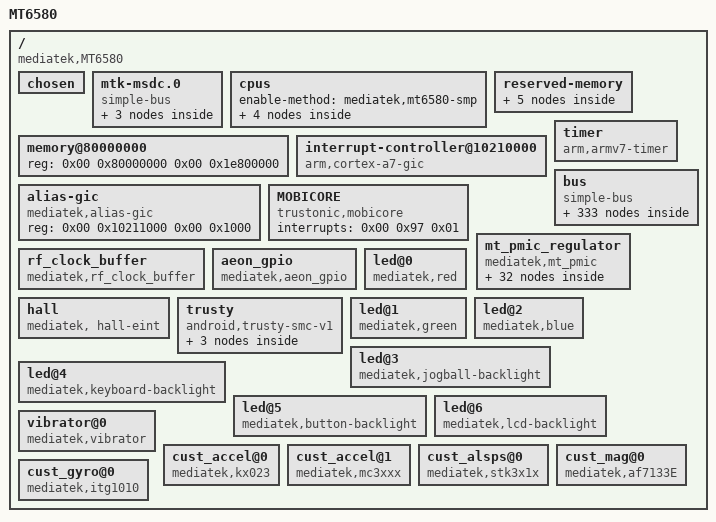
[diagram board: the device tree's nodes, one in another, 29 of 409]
/dts-v1/;

/ {
	model = "MT6580";
	compatible = "mediatek,MT6580";
	interrupt-parent = <0x01>;
	#address-cells = <0x02>;
	#size-cells = <0x02>;

	chosen {
		bootargs = "console=tty0 console=ttyMT0,921600n1 root=/dev/ram initrd=0x84000000,0x400000 loglevel=8";
		atag,videolfb-fb_base = <0x9e800000>;
		atag,videolfb-islcmfound = <0x01>;
		atag,videolfb-fps = <0x1770>;
		atag,videolfb-vramSize = <0x1800000>;
		atag,videolfb-lcmname = "nt35590_AUO";
	};

	mtk-msdc.0 {
		compatible = "simple-bus";
		#address-cells = <0x01>;
		#size-cells = <0x01>;
		ranges = <0x00 0x00 0x00 0xffffffff>;

		msdc0@11120000 {
			compatible = "mediatek,mt6580-mmc";
			reg = <0x11120000 0x10000 0x10001e84 0x02>;
			interrupts = <0x00 0x26 0x08>;
			status = "okay";
			clk_src = [07];
			bus-width = <0x08>;
			max-frequency = <0xc65d400>;
			cap-mmc-highspeed;
			msdc-sys-suspend;
			mmc-hs200-1_8v;
			non-removable;
			pinctl = <0x02>;
			register_setting = <0x03>;
			host_function = [00];
			bootable;
		};

		msdc1@11130000 {
			compatible = "mediatek,mt6580-mmc";
			reg = <0x11130000 0x10000 0x10001e84 0x02>;
			interrupts = <0x00 0x27 0x08>;
			cd-gpios = <0x04 0x0c 0x00>;
			status = "okay";
			clk_src = [02];
			bus-width = <0x04>;
			max-frequency = <0xc65d400>;
			msdc-sys-suspend;
			cap-sd-highspeed;
			sd-uhs-sdr12;
			sd-uhs-sdr25;
			sd-uhs-sdr50;
			sd-uhs-sdr104;
			non-removable;
			pinctl = <0x05>;
			pinctl_sdr104 = <0x06>;
			pinctl_sdr50 = <0x07>;
			pinctl_ddr50 = <0x08>;
			register_setting = <0x09>;
			host_function = [01];
			cd_level = [00];
		};

		default {
			compatible = "mediatek,msdc1_ins-eint";
			interrupt-parent = <0x0a>;
			interrupts = <0x0c 0x08>;
			debounce = <0x0c 0x3e8>;
			status = "okay";
		};
	};

	cpus {
		#address-cells = <0x01>;
		#size-cells = <0x00>;
		enable-method = "mediatek,mt6580-smp";

		cpu@0 {
			device_type = "cpu";
			compatible = "arm,cortex-a7";
			reg = <0x00>;
			clock-frequency = <0x6553f100>;
		};

		cpu@1 {
			device_type = "cpu";
			compatible = "arm,cortex-a7";
			reg = <0x01>;
			clock-frequency = <0x6553f100>;
		};

		cpu@2 {
			device_type = "cpu";
			compatible = "arm,cortex-a7";
			reg = <0x02>;
			clock-frequency = <0x6553f100>;
		};

		cpu@3 {
			device_type = "cpu";
			compatible = "arm,cortex-a7";
			reg = <0x03>;
			clock-frequency = <0x6553f100>;
		};
	};

	memory@80000000 {
		device_type = "memory";
		reg = <0x00 0x80000000 0x00 0x1e800000>;
	};

	reserved-memory {
		#address-cells = <0x02>;
		#size-cells = <0x02>;
		ranges;

		consys-reserve-memory {
			compatible = "mediatek,consys-reserve-memory";
			no-map;
			size = <0x00 0x200000>;
			alignment = <0x00 0x200000>;
		};

		reserve-memory-ccci_md1 {
			compatible = "mediatek,reserve-memory-ccci_md1";
			no-map;
			size = <0x00 0x1800000>;
			alignment = <0x00 0x2000000>;
			alloc-ranges = <0x00 0x80000000 0x00 0x80000000>;
		};

		pstore-reserved-memory@83f10000 {
			compatible = "mediatek,pstore";
			reg = <0x00 0x83f10000 0x00 0xe0000>;
		};

		ram_console-reserved-memory@83f00000 {
			compatible = "mediatek,ram_console";
			reg = <0x00 0x83f00000 0x00 0x10000>;
		};

		minirdump-reserved-memory@83ff0000 {
			compatible = "mediatek, minirdump";
			reg = <0x00 0x83ff0000 0x00 0x10000>;
		};
	};

	interrupt-controller@10210000 {
		compatible = "arm,cortex-a7-gic";
		#interrupt-cells = <0x03>;
		#address-cells = <0x00>;
		interrupt-controller;
		reg = <0x00 0x10211000 0x00 0x1000 0x00 0x10212000 0x00 0x1000 0x00 0x10200100 0x00 0x1000>;
		interrupts = <0x01 0x09 0xf04>;
		linux,phandle = <0x01>;
		phandle = <0x01>;
	};

	alias-gic {
		compatible = "mediatek,alias-gic";
		reg = <0x00 0x10211000 0x00 0x1000>;
	};

	timer {
		compatible = "arm,armv7-timer";
		interrupts = <0x01 0x0d 0x08 0x01 0x0e 0x08 0x01 0x0b 0x08 0x01 0x0a 0x08>;
		clock-frequency = <0xc65d40>;
	};

	bus {
		compatible = "simple-bus";
		#address-cells = <0x01>;
		#size-cells = <0x01>;
		ranges = <0x00 0x00 0x00 0xffffffff>;

		chipid@08000000 {
			compatible = "mediatek,chipid";
			reg = <0x8000000 0x04 0x8000004 0x04 0x8000008 0x04 0x800000c 0x04>;
		};

		TOPCKGEN@0x10000000 {
			compatible = "mediatek,TOPCKGEN";
			reg = <0x10000000 0x1000>;
		};

		INFRACFG_AO@0x10001000 {
			compatible = "mediatek,INFRACFG_AO";
			reg = <0x10001000 0x1000>;
		};

		bat_meter {
			compatible = "mediatek,bat_meter";
		};

		BAT_NOTIFY {
			compatible = "mediatek,bat_notify";
		};

		bat_comm {
			compatible = "mediatek,battery";
		};

		keypad@10002000 {
			compatible = "mediatek,mt6580-keypad";
			reg = <0x10002000 0x1000>;
			interrupts = <0x00 0x6d 0x02>;
			mediatek,kpd-key-debounce = <0x400>;
			mediatek,kpd-sw-pwrkey = <0x74>;
			mediatek,kpd-hw-pwrkey = <0x08>;
			mediatek,kpd-use-extend-type = <0x00>;
			mediatek,kpd-hw-map-num = <0x48>;
			mediatek,kpd-hw-init-map = <0x73 0x00 0x00 0x00 0x00 0x00 0x00 0x00 0x00 0x72 0x00 0x00 0x00 0x00 0x00 0x00 0x00 0x00 0x00 0x00 0x00 0x00 0x00 0x00 0x00 0x00 0x00 0x00 0x00 0x00 0x00 0x00 0x00 0x00 0x00 0x00 0x00 0x00 0x00 0x00 0x00 0x00 0x00 0x00 0x00 0x00 0x00 0x00 0x00 0x00 0x00 0x00 0x00 0x00 0x00 0x00 0x00 0x00 0x00 0x00 0x00 0x00 0x00 0x00 0x00 0x00 0x00 0x00 0x00 0x00 0x00 0x00>;
			mediatek,kpd-pwrkey-eint-gpio = <0x00>;
			mediatek,kpd-pwkey-gpio-din = <0x00>;
			mediatek,kpd-hw-dl-key0 = <0x00>;
			mediatek,kpd-hw-dl-key1 = <0x09>;
			mediatek,kpd-hw-dl-key2 = <0x08>;
			mediatek,kpd-hw-recovery-key = <0x00>;
			mediatek,kpd-hw-factory-key = <0x09>;
			status = "okay";
		};

		PERICFG@0x10003000 {
			compatible = "mediatek,PERICFG";
			reg = <0x10003000 0x1000>;
		};

		RESERVED@0x10004000 {
			compatible = "mediatek,RESERVED";
			reg = <0x10004000 0x1000>;
		};

		gpio {
			compatible = "mediatek,gpio_usage_mapping";
			GPIO_SIM1_SCLK = <0x16>;
			GPIO_SIM1_SIO = <0x17>;
			GPIO_SIM2_SIO = <0x18>;
			GPIO_SIM2_SCLK = <0x19>;
		};

		gpio@0x10005000 {
			compatible = "mediatek,gpio";
			reg = <0x10005000 0x1000>;
		};

		SLEEP@0x10006000 {
			compatible = "mediatek,SLEEP";
			reg = <0x10006000 0x1000>;
			interrupts = <0x00 0x58 0x08 0x00 0x59 0x08 0x00 0x5a 0x08 0x00 0x5b 0x08>;
		};

		TOPRGU@0x10007000 {
			compatible = "mediatek,TOPRGU";
			reg = <0x10007000 0x1000>;
			interrupts = <0x00 0x9d 0x02>;
		};

		APXGPT@0x10008000 {
			compatible = "mediatek,APXGPT";
			reg = <0x10008000 0x1000>;
			interrupts = <0x00 0x5c 0x08>;
			clock-frequency = <0xc65d40>;
		};

		EFUSEC@0x10009000 {
			compatible = "mediatek,EFUSEC";
			reg = <0x10009000 0x1000>;
		};

		hacc@0x1000A000 {
			compatible = "mediatek,hacc";
			reg = <0x1000a000 0x1000>;
			interrupts = <0x00 0x6e 0x00>;
		};

		cpu_dbgapb@10170000 {
			compatible = "mediatek,mt6580-dbg_debug";
			num = <0x04>;
			reg = <0x10170000 0x2000 0x10172000 0x2000 0x10174000 0x2000 0x10176000 0x2000>;
		};

		eintc@1000b000 {
			compatible = "mediatek,mt-eic";
			reg = <0x1000b000 0x1000>;
			interrupts = <0x00 0x5e 0x04>;
			#interrupt-cells = <0x02>;
			interrupt-controller;
			mediatek,max_eint_num = <0x1a>;
			mediatek,mapping_table_entry = <0x53>;
			mediatek,mapping_table = <0x00 0x00 0x01 0x01 0x02 0x02 0x03 0x03 0x04 0x04 0x05 0x05 0x06 0x06 0x07 0x07 0x08 0x08 0x09 0x09 0x0a 0x0a 0x0b 0x0b 0x0c 0x0c 0x0d 0x0d 0x0e 0x0e 0x0f 0x0f 0x10 0x00 0x11 0x01 0x12 0x02 0x13 0x03 0x14 0x04 0x15 0x05 0x16 0x06 0x17 0x07 0x18 0x08 0x19 0x09 0x1a 0x0a 0x1b 0x0b 0x1c 0x0c 0x1d 0x0d 0x1e 0x0e 0x1f 0x0f 0x20 0x00 0x21 0x01 0x22 0x02 0x23 0x03 0x24 0x04 0x25 0x05 0x26 0x06 0x27 0x07 0x28 0x08 0x29 0x09 0x2a 0x0a 0x2b 0x0b 0x2c 0x0c 0x2d 0x0d 0x2e 0x0e 0x2f 0x0f 0x30 0x00 0x31 0x01 0x32 0x02 0x33 0x03 0x34 0x03 0x35 0x04 0x36 0x05 0x37 0x06 0x38 0x07 0x39 0x08 0x3a 0x0a 0x3b 0x0b 0x3c 0x0c 0x3d 0x0d 0x3e 0x0e 0x3f 0x0f 0x40 0x00 0x41 0x01 0x42 0x02 0x43 0x03 0x44 0x10 0x45 0x04 0x46 0x05 0x47 0x06 0x48 0x07 0x49 0x08 0x4a 0x09 0x4b 0x0a 0x4c 0x0b 0x4d 0x0c 0x4e 0x0d 0x51 0x00 0x52 0x01 0x53 0x02 0x54 0x03>;
			mediatek,builtin_entry = <0x0b>;
			mediatek,builtin_mapping = <0x00 0x03 0x14 0x01 0x03 0x12 0x07 0x04 0x14 0x08 0x04 0x12 0x09 0x03 0x14 0x0a 0x03 0x12 0x18 0x05 0x14 0x19 0x05 0x12 0x4d 0x02 0x14 0x4e 0x02 0x12 0x0d 0x01 0x11>;
			linux,phandle = <0x0a>;
			phandle = <0x0a>;

			pmic@13 {
				compatible = "mediatek, pmic-eint";
				interrupt-parent = <0x0a>;
				interrupts = <0x0d 0x01>;
				debounce = <0x0d 0x3e8>;
			};
		};

		ap_ccif0@1000C000 {
			compatible = "mediatek,ap_ccif0";
			reg = <0x1000c000 0x1000 0x1000d000 0x1000>;
			interrupts = <0x00 0x5d 0x08 0x00 0x98 0x02>;
			mediatek,ccif_capability = <0x02>;
			mediatek,md_smem_size = <0x200000>;
		};

		MCUSYS_CFGREG@0x1020000 {
			compatible = "mediatek,MCUSYS_CFGREG_BASE";
			reg = <0x1020000 0x200>;
		};

		mcucfg@10200000 {
			compatible = "mediatek,mt6580-mcucfg";
			reg = <0x10200000 0x200>;
		};

		AES@0x1000E000 {
			compatible = "mediatek,AES";
			reg = <0x1000e000 0x1000>;
		};

		PWRAP@0x1000F000 {
			compatible = "mediatek,PWRAP";
			reg = <0x1000f000 0x1000>;
			interrupts = <0x00 0x6c 0x00>;
		};

		DEVAPC_AO@0x10010000 {
			compatible = "mediatek,DEVAPC_AO";
			reg = <0x10010000 0x1000>;
		};

		MIPI_CONFG@0x10011000 {
			compatible = "mediatek,MIPI_CONFG";
			reg = <0x10011000 0x1000>;
		};

		INFRA_MBIST@0x10012000 {
			compatible = "mediatek,INFRA_MBIST";
			reg = <0x10012000 0x1000>;
		};

		RESERVED@0x10013000 {
			compatible = "mediatek,RESERVED";
			reg = <0x10013000 0x1000>;
		};

		IOCFG_T@0x10014000 {
			compatible = "mediatek,IOCFG_T";
			reg = <0x10014000 0x1000>;
		};

		IOCFG_B@0x10015000 {
			compatible = "mediatek,IOCFG_B";
			reg = <0x10015000 0x1000>;
		};

		IOCFG_L@0x10016000 {
			compatible = "mediatek,IOCFG_L";
			reg = <0x10016000 0x1000>;
		};

		IOCFG_R@0x10017000 {
			compatible = "mediatek,IOCFG_R";
			reg = <0x10017000 0x1000>;
		};

		APMIXED@0x10018000 {
			compatible = "mediatek,APMIXED";
			reg = <0x10018000 0x1000>;
		};

		MCUCFG@0x10200000 {
			compatible = "mediatek,MCUCFG";
			reg = <0x10200000 0x1000>;
		};

		INFRACFG@0x10201000 {
			compatible = "mediatek,INFRACFG";
			reg = <0x10201000 0x1000>;
		};

		sys_cirq@10202000 {
			compatible = "mediatek,mt6580-sys_cirq\0mediatek,mt6735-sys_cirq";
			reg = <0x10202000 0x1000>;
			interrupts = <0x00 0x9e 0x08>;
			mediatek,cirq_num = <0x7e>;
			mediatek,spi_start_offset = <0x20>;
		};

		m4u@10203000 {
			cell-index = <0x00>;
			compatible = "mediatek,m4u";
			reg = <0x10203000 0x1000>;
			interrupts = <0x00 0x51 0x08>;
		};

		DEVAPC@0x10204000 {
			compatible = "mediatek,DEVAPC";
			reg = <0x10204000 0x1000>;
			interrupts = <0x00 0x4a 0x08>;
		};

		EMI@0x10205000 {
			compatible = "mediatek,EMI";
			reg = <0x10205000 0x1000>;
			interrupts = <0x00 0x4c 0x04>;
		};

		DRAMC_NAO@0x10206000 {
			compatible = "mediatek,DRAMC_NAO";
			reg = <0x10206000 0x1000>;
		};

		DRAMC0@0x10207000 {
			compatible = "mediatek,DRAMC0";
			reg = <0x10207000 0x1000>;
		};

		DDRPHY@0x10208000 {
			compatible = "mediatek,DDRPHY";
			reg = <0x10208000 0x1000>;
		};

		SRAMROM@0x10209000 {
			compatible = "mediatek,SRAMROM";
			reg = <0x10209000 0x1000>;
		};

		simswitch@0 {
			compatible = "mediatek,sim_switch";
			pinctrl-names = "default\0hot_plug_mode1";
			pinctrl-0 = <0x0b>;
			pinctrl-1 = <0x0c>;
		};

		gce@1020a000 {
			compatible = "mediatek,gce";
			reg = <0x1020a000 0x1000>;
			interrupts = <0x00 0x55 0x08 0x00 0x56 0x08>;
			disp_mutex_reg = <0x14015000 0x1000>;
			g3d_config_base = <0x13000000 0x00 0xffff0000>;
			mmsys_config_base = <0x14000000 0x01 0xffff0000>;
			disp_dither_base = <0x14010000 0x02 0xffff0000>;
			mm_na_base = <0x14020000 0x03 0xffff0000>;
			imgsys_base = <0x15000000 0x04 0xffff0000>;
			vdec_gcon_base = <0x16000000 0x05 0xffff0000>;
			venc_gcon_base = <0x17000000 0x06 0xffff0000>;
			conn_peri_base = <0x18000000 0x07 0xffff0000>;
			topckgen_base = <0x10000000 0x08 0xffff0000>;
			kp_base = <0x10010000 0x09 0xffff0000>;
			scp_sram_base = <0x10020000 0x0a 0xffff0000>;
			infra_na3_base = <0x10030000 0x0b 0xffff0000>;
			infra_na4_base = <0x10040000 0x0c 0xffff0000>;
			scp_base = <0x10050000 0x0d 0xffff0000>;
			mcucfg_base = <0x10200000 0x0e 0xffff0000>;
			gcpu_base = <0x10210000 0x0f 0xffff0000>;
			usb0_base = <0x11200000 0x10 0xffff0000>;
			usb_sif_base = <0x11210000 0x11 0xffff0000>;
			audio_base = <0x11220000 0x12 0xffff0000>;
			msdc0_base = <0x11230000 0x13 0xffff0000>;
			msdc1_base = <0x11240000 0x14 0xffff0000>;
			msdc2_base = <0x11250000 0x15 0xffff0000>;
			msdc3_base = <0x11260000 0x16 0xffff0000>;
			pwm_sw_base = <0x1100f000 0x63 0xfffff000>;
			mdp_rdma0_sof = <0x00>;
			mdp_rsz0_sof = <0x01>;
			mdp_rsz1_sof = <0x02>;
			mdp_tdshp_sof = <0x03>;
			mdp_wdma_sof = <0x04>;
			mdp_wrot_sof = <0x05>;
			disp_ovl0_sof = <0x06>;
			disp_rdma0_sof = <0x08>;
			disp_wdma0_sof = <0x0a>;
			disp_color_sof = <0x0c>;
			disp_aal_sof = <0x0d>;
			disp_gamma_sof = <0x0e>;
			disp_dither_sof = <0x0f>;
			disp_pwm0_sof = <0x11>;
			mdp_rdma0_frame_done = <0x12>;
			mdp_rsz0_frame_done = <0x13>;
			mdp_rsz1_frame_done = <0x14>;
			mdp_tdshp_frame_done = <0x15>;
			mdp_wdma_frame_done = <0x16>;
			mdp_wrot_write_frame_done = <0x17>;
			mdp_wrot_read_frame_done = <0x18>;
			disp_ovl0_frame_done = <0x19>;
			disp_rdma0_frame_done = <0x1b>;
			disp_wdma0_frame_done = <0x1d>;
			disp_color_frame_done = <0x1f>;
			disp_aal_frame_done = <0x20>;
			disp_gamma_frame_done = <0x21>;
			disp_dither_frame_done = <0x22>;
			disp_dsi0_frame_done = <0x25>;
			stream_done_0 = <0x26>;
			stream_done_1 = <0x27>;
			stream_done_2 = <0x28>;
			stream_done_3 = <0x29>;
			stream_done_4 = <0x2a>;
			stream_done_5 = <0x2b>;
			stream_done_6 = <0x2c>;
			stream_done_7 = <0x2d>;
			stream_done_8 = <0x2e>;
			stream_done_9 = <0x2f>;
			buf_underrun_event_0 = <0x30>;
			dsi0_te_event = <0x32>;
			isp_frame_done_p2_1 = <0x42>;
			isp_frame_done_p2_0 = <0x43>;
			seninf_cam0_fifo_full = <0x49>;
			apxgpt2_count = <0x10008028>;
		};

		bus_dbg@1020b000 {
			compatible = "mediatek,bus_dbg-v2";
			reg = <0x1020b000 0x1000>;
			interrupts = <0x00 0x49 0x08>;
			two_stage_timeout = <0x01>;
		};

		TRNG@0x1020C000 {
			compatible = "mediatek,TRNG";
			reg = <0x1020c000 0x1000>;
			interrupts = <0x00 0x57 0x08>;
		};

		MCUCFG_BIU@0x1020D000 {
			compatible = "mediatek,MCUCFG_BIU";
			reg = <0x1020d000 0x1000>;
		};

		DBGSYS_DEM@0x1011A000 {
			compatible = "mediatek,DBGSYS_DEM";
			reg = <0x1011a000 0x1000>;
		};

		DBGSYS_CTI@0x10112000 {
			compatible = "mediatek,DBGSYS_CTI";
			reg = <0x10112000 0x1000>;
		};

		DBGSYS_DAPROM@0x10110000 {
			compatible = "mediatek,DBGSYS_DAPROM";
			reg = <0x10110000 0x1000>;
		};

		DBGSYS_CPU@0x10160000 {
			compatible = "mediatek,DBGSYS_CPU";
			reg = <0x10160000 0x20000>;
		};

		DBGSYS_MDSYS@0x10120000 {
			compatible = "mediatek,DBGSYS_MDSYS";
			reg = <0x10120000 0x10000>;
		};

		dma@0x11000000 {
			compatible = "mediatek,ap_dma";
			reg = <0x11000000 0x1000>;
			interrupts = <0x00 0x30 0x08>;
		};

		NFI@0x11001000 {
			compatible = "mediatek,NFI";
			reg = <0x11001000 0x1000>;
			interrupts = <0x00 0x2f 0x08>;
		};

		NFIECC@0x11002000 {
			compatible = "mediatek,NFIECC";
			reg = <0x11002000 0x1000>;
			interrupts = <0x00 0x2e 0x08>;
		};

		adc_hw@11003000 {
			compatible = "mediatek,mt6735-auxadc";
			reg = <0x11003000 0x1000>;
			interrupts = <0x00 0x23 0x02>;

			adc_channel@ {
				compatible = "mediatek,adc_channel";
				mediatek,temperature0 = <0x00>;
				mediatek,temperature1 = <0x01>;
				status = "okay";
			};
		};

		FHCTL@0x11004000 {
			compatible = "mediatek,FHCTL";
			reg = <0x11004000 0x1000>;
		};

		AP_UART0@0x11005000 {
			cell-index = <0x00>;
			compatible = "mediatek,AP_UART0";
			reg = <0x11005000 0x1000>;
			interrupts = <0x00 0x2c 0x08>;
		};

		AP_UART1@0x11006000 {
			cell-index = <0x01>;
			compatible = "mediatek,AP_UART1";
			reg = <0x11006000 0x1000>;
			interrupts = <0x00 0x2d 0x08>;
		};

		AP_DMA_UART0_TX@0x11000480 {
			compatible = "mediatek,AP_DMA_UART0_TX";
			reg = <0x11000480 0x80>;
			interrupts = <0x00 0x38 0x08>;
		};

		AP_DMA_UART0_RX@0x11000500 {
			compatible = "mediatek,AP_DMA_UART0_RX";
			reg = <0x11000500 0x80>;
			interrupts = <0x00 0x39 0x08>;
		};

		AP_DMA_UART1_TX@0x11000580 {
			compatible = "mediatek,AP_DMA_UART1_TX";
			reg = <0x11000580 0x80>;
			interrupts = <0x00 0x3a 0x08>;
		};

		AP_DMA_UART1_RX@0x11000600 {
			compatible = "mediatek,AP_DMA_UART1_RX";
			reg = <0x11000600 0x80>;
			interrupts = <0x00 0x3b 0x08>;
		};

		PWM@0x11008000 {
			compatible = "mediatek,PWM";
			reg = <0x11008000 0x1000>;
			interrupts = <0x00 0x24 0x08>;
		};

		syscfg_pctl_a@0x10005000 {
			compatible = "mediatek,mt6580-pctl-a-syscfg\0syscon";
			reg = <0x10211000 0x1000>;
			linux,phandle = <0x0d>;
			phandle = <0x0d>;
		};

		pinctrl@0x10005000 {
			compatible = "mediatek,mt6580-pinctrl";
			reg = <0x10005000 0x1000>;
			mediatek,pctl-regmap = <0x0d>;
			pins-are-numbered;
			gpio-controller;
			#gpio-cells = <0x02>;
			linux,phandle = <0x04>;
			phandle = <0x04>;

			ssw0default {
				linux,phandle = <0x0b>;
				phandle = <0x0b>;
			};

			ssw@1 {
				linux,phandle = <0x0c>;
				phandle = <0x0c>;

				pins_cmd0_dat {
					pins = <0x107>;
				};

				pins_cmd1_dat {
					pins = <0xf00>;
				};
			};

			aeon@0 {
				linux,phandle = <0x4c>;
				phandle = <0x4c>;
			};

			aeon@1 {
				linux,phandle = <0x4d>;
				phandle = <0x4d>;
			};

			aeon@2 {
				linux,phandle = <0x4e>;
				phandle = <0x4e>;
			};

			aeon@3 {
				linux,phandle = <0x4f>;
				phandle = <0x4f>;
			};

			aeon@4 {
				linux,phandle = <0x50>;
				phandle = <0x50>;

				pins_cmd_dat {
					pins = <0x1200>;
					slew-rate = <0x01>;
					output-low;
				};
			};

			aeon@5 {
				linux,phandle = <0x51>;
				phandle = <0x51>;

				pins_cmd_dat {
					pins = <0x1200>;
					slew-rate = <0x01>;
					output-high;
				};
			};

			aeon@6 {
				linux,phandle = <0x52>;
				phandle = <0x52>;

				pins_cmd_dat {
					pins = <0xa00>;
					slew-rate = <0x01>;
					output-low;
				};
			};

			aeon@7 {
				linux,phandle = <0x53>;
				phandle = <0x53>;

				pins_cmd_dat {
					pins = <0xa00>;
					slew-rate = <0x01>;
					output-high;
				};
			};

			aeon@8 {
				linux,phandle = <0x54>;
				phandle = <0x54>;

				pins_cmd_dat {
					pins = <0xa05>;
				};
			};

			hallpincfg {
				linux,phandle = <0x56>;
				phandle = <0x56>;
			};

			halldefaultcfg {
				linux,phandle = <0x55>;
				phandle = <0x55>;
			};

			mmc0@default {
				linux,phandle = <0x02>;
				phandle = <0x02>;

				pins_cmd {
					drive-strength = [02];
				};

				pins_dat {
					drive-strength = [02];
				};

				pins_clk {
					drive-strength = [02];
				};

				pins_rst {
					drive-strength = [02];
				};

				pins_ds {
					drive-strength = [02];
				};
			};

			mmc0@register_default {
				dat0rddly = [00];
				dat1rddly = [00];
				dat2rddly = [00];
				dat3rddly = [00];
				dat4rddly = [00];
				dat5rddly = [00];
				dat6rddly = [00];
				dat7rddly = [00];
				datwrddly = [00];
				cmdrrddly = [00];
				cmdrddly = [00];
				cmd_edge = [01];
				rdata_edge = [01];
				wdata_edge = [01];
				ett-hs200-cells = <0x0c>;
				ett-hs200-default = <0xb0 0x380 0x00 0xb0 0x7c00 0x00 0xb4 0x38 0x01 0x04 0x02 0x01 0xf0 0x1f0000 0x00 0xf0 0x7c00000 0x00 0xb4 0x07 0x01 0xf0 0x1f 0x00 0x04 0x100 0x01 0xf8 0x1f000000 0x00 0xf0 0x1f00 0x00 0xb0 0x08 0x01>;
				linux,phandle = <0x03>;
				phandle = <0x03>;
			};

			mmc1@default {
				linux,phandle = <0x05>;
				phandle = <0x05>;

				pins_cmd {
					drive-strength = [03];
				};

				pins_dat {
					drive-strength = [03];
				};

				pins_clk {
					drive-strength = [03];
				};
			};

			mmc1@sdr104 {
				linux,phandle = <0x06>;
				phandle = <0x06>;

				pins_cmd {
					drive-strength = [02];
				};

				pins_dat {
					drive-strength = [02];
				};

				pins_clk {
					drive-strength = [03];
				};
			};

			mmc1@sdr50 {
				linux,phandle = <0x07>;
				phandle = <0x07>;

				pins_cmd {
					drive-strength = [02];
				};

				pins_dat {
					drive-strength = [02];
				};

				pins_clk {
					drive-strength = [03];
				};
			};

			mmc1@ddr50 {
				linux,phandle = <0x08>;
				phandle = <0x08>;

				pins_cmd {
					drive-strength = [02];
				};

				pins_dat {
					drive-strength = [02];
				};

				pins_clk {
					drive-strength = [03];
				};
			};

			mmc1@register_default {
				dat0rddly = [00];
				dat1rddly = [00];
				dat2rddly = [00];
				dat3rddly = [00];
				datwrddly = [00];
				cmdrrddly = [00];
				cmdrddly = [00];
				cmd_edge = [01];
				rdata_edge = [01];
				wdata_edge = [01];
				linux,phandle = <0x09>;
				phandle = <0x09>;
			};

			alspspincfg {
				linux,phandle = <0x38>;
				phandle = <0x38>;

				pins_cmd_dat {
					pins = <0x606>;
					slew-rate = <0x00>;
					bias-pull-up = <0x00>;
				};
			};

			alspsdefaultcfg {
				linux,phandle = <0x37>;
				phandle = <0x37>;
			};

			gyropincfg {
				linux,phandle = <0x3a>;
				phandle = <0x3a>;

				pins_cmd_dat {
					pins = <0x1100>;
					slew-rate = <0x00>;
					bias-pull-down = <0x00>;
				};
			};

			gyrodefaultcfg {
				linux,phandle = <0x39>;
				phandle = <0x39>;
			};

			eint0default {
				linux,phandle = <0x15>;
				phandle = <0x15>;
			};

			eint@0 {
				linux,phandle = <0x16>;
				phandle = <0x16>;

				pins_cmd_dat {
					pins = <0x06>;
					slew-rate = <0x00>;
					bias-disable;
				};
			};

			toucheint5default {
				linux,phandle = <0x0f>;
				phandle = <0x0f>;
			};

			toucheint@5 {
				linux,phandle = <0x10>;
				phandle = <0x10>;

				pins_cmd_dat {
					pins = <0x506>;
					slew-rate = <0x00>;
					bias-disable;
				};
			};

			eintoutput0 {
				linux,phandle = <0x11>;
				phandle = <0x11>;

				pins_cmd_dat {
					pins = <0x500>;
					slew-rate = <0x01>;
					output-low;
				};
			};

			eintoutput1 {
				linux,phandle = <0x12>;
				phandle = <0x12>;

				pins_cmd_dat {
					pins = <0x500>;
					slew-rate = <0x01>;
					output-high;
				};
			};

			rstoutput0 {
				linux,phandle = <0x13>;
				phandle = <0x13>;

				pins_cmd_dat {
					pins = <0x200>;
					slew-rate = <0x01>;
					output-low;
				};
			};

			rstoutput1 {
				linux,phandle = <0x14>;
				phandle = <0x14>;

				pins_cmd_dat {
					pins = <0x200>;
					slew-rate = <0x01>;
					output-high;
				};
			};

			audiodefault {
				linux,phandle = <0x1f>;
				phandle = <0x1f>;
			};

			pmicclkmode0 {
				linux,phandle = <0x20>;
				phandle = <0x20>;

				pins_cmd0_dat {
					pins = <0x1a00>;
				};

				pins_cmd1_dat {
					pins = <0x1c00>;
				};

				pins_cmd2_dat {
					pins = <0x1b00>;
				};
			};

			pmicclkmode1 {
				linux,phandle = <0x21>;
				phandle = <0x21>;

				pins_cmd0_dat {
					pins = <0x1a01>;
				};

				pins_cmd1_dat {
					pins = <0x1c01>;
				};

				pins_cmd2_dat {
					pins = <0x1b01>;
				};
			};

			cam0@0 {
				linux,phandle = <0x27>;
				phandle = <0x27>;

				pins_cmd_dat {
					pins = <0x4900>;
					slew-rate = <0x01>;
					output-low;
				};
			};

			cam0@1 {
				linux,phandle = <0x28>;
				phandle = <0x28>;

				pins_cmd_dat {
					pins = <0x4900>;
					slew-rate = <0x01>;
					output-high;
				};
			};

			cam0@2 {
				linux,phandle = <0x29>;
				phandle = <0x29>;

				pins_cmd_dat {
					pins = <0x4700>;
					slew-rate = <0x01>;
					output-low;
				};
			};

			cam0@3 {
				linux,phandle = <0x2a>;
				phandle = <0x2a>;

				pins_cmd_dat {
					pins = <0x4700>;
					slew-rate = <0x01>;
					output-high;
				};
			};

			cam1@0 {
				linux,phandle = <0x2b>;
				phandle = <0x2b>;

				pins_cmd_dat {
					pins = <0x4c00>;
					slew-rate = <0x01>;
					output-low;
				};
			};

			cam1@1 {
				linux,phandle = <0x2c>;
				phandle = <0x2c>;

				pins_cmd_dat {
					pins = <0x4c00>;
					slew-rate = <0x01>;
					output-high;
				};
			};

			cam1@2 {
				linux,phandle = <0x2d>;
				phandle = <0x2d>;

				pins_cmd_dat {
					pins = <0x4a00>;
					slew-rate = <0x01>;
					output-low;
				};
			};

			cam1@3 {
				linux,phandle = <0x2e>;
				phandle = <0x2e>;

				pins_cmd_dat {
					pins = <0x4a00>;
					slew-rate = <0x01>;
					output-high;
				};
			};

			cam@0 {
				linux,phandle = <0x2f>;
				phandle = <0x2f>;
			};

			cam@1 {
				linux,phandle = <0x30>;
				phandle = <0x30>;
			};

			camdefault {
				linux,phandle = <0x26>;
				phandle = <0x26>;
			};

			cam1serial@0 {
				linux,phandle = <0x31>;
				phandle = <0x31>;

				pins_cmd_dat {
					pins = <0x2302>;
				};

				pins_cmd_dat1 {
					pins = <0x2402>;
				};

				pins_cmd_dat2 {
					pins = <0x2502>;
				};

				pins_cmd_dat3 {
					pins = <0x2602>;
				};

				pins_cmd_dat4 {
					pins = <0x2702>;
				};
			};

			cam1mipi@0 {
				linux,phandle = <0x32>;
				phandle = <0x32>;

				pins_cmd_dat {
					pins = <0x2301>;
				};

				pins_cmd_dat1 {
					pins = <0x2401>;
				};

				pins_cmd_dat2 {
					pins = <0x2501>;
				};

				pins_cmd_dat3 {
					pins = <0x2601>;
				};

				pins_cmd_dat4 {
					pins = <0x2701>;
				};

				pins_cmd_dat5 {
					pins = <0x2801>;
				};
			};

			mclk1enable@0 {
				linux,phandle = <0x33>;
				phandle = <0x33>;

				pins_cmd_dat {
					pins = <0x4801>;
				};
			};

			mclk1disable@0 {
				linux,phandle = <0x34>;
				phandle = <0x34>;

				pins_cmd_dat {
					pins = <0x4800>;
				};
			};

			mclk2enable@0 {
				linux,phandle = <0x35>;
				phandle = <0x35>;

				pins_cmd_dat {
					pins = <0x4b01>;
				};
			};

			mclk2disable@0 {
				linux,phandle = <0x36>;
				phandle = <0x36>;

				pins_cmd_dat {
					pins = <0x4b00>;
				};
			};

			default {
				linux,phandle = <0x1b>;
				phandle = <0x1b>;
			};

			gpslna@0 {
				linux,phandle = <0x1c>;
				phandle = <0x1c>;

				pins_cmd_dat {
					pins = <0x5400>;
					slew-rate = <0x00>;
					bias-disable;
					output-low;
				};
			};

			gpslna@1 {
				linux,phandle = <0x1d>;
				phandle = <0x1d>;

				pins_cmd_dat {
					pins = <0x5300>;
					slew-rate = <0x01>;
					output-high;
				};
			};

			gpslna@2 {
				linux,phandle = <0x1e>;
				phandle = <0x1e>;

				pins_cmd_dat {
					pins = <0x5300>;
					slew-rate = <0x01>;
					output-low;
				};
			};
		};

		i2c@11009000 {
			compatible = "mediatek,mt6580-i2c\0mediatek,i2c0";
			cell-index = <0x00>;
			reg = <0x11009000 0x1000>;
			interrupts = <0x00 0x28 0x08 0x00 0x32 0x08>;
			clock-div = <0x0a>;
			#address-cells = <0x01>;
			#size-cells = <0x00>;

			camera_main@10 {
				compatible = "mediatek,camera_main";
				reg = <0x10>;
				status = "okay";
			};

			camera_main_af@0c {
				compatible = "mediatek,camera_main_af";
				reg = <0x0c>;
				status = "okay";
			};

			camera_sub@36 {
				compatible = "mediatek,camera_sub";
				reg = <0x36>;
				status = "okay";
			};
		};

		i2c@1100a000 {
			compatible = "mediatek,mt6580-i2c\0mediatek,i2c1";
			cell-index = <0x01>;
			reg = <0x1100a000 0x1000>;
			interrupts = <0x00 0x29 0x08 0x00 0x33 0x08>;
			clock-div = <0x0a>;
			#address-cells = <0x01>;
			#size-cells = <0x00>;

			cap_touch@5d {
				compatible = "mediatek,cap_touch";
				reg = <0x5d>;
				status = "okay";
			};

			ext_buck@60 {
				compatible = "mediatek,ext_buck";
				reg = <0x60>;
				status = "okay";
			};

			ft_touch@38 {
				compatible = "mediatek,ft_touch";
				reg = <0x38>;
				status = "okay";
			};

			msg_touch@26 {
				compatible = "mediatek,msg_touch";
				reg = <0x26>;
				status = "okay";
			};

			ilitek_touch@41 {
				compatible = "mediatek,ilitek_touch";
				reg = <0x41>;
				status = "okay";
			};
		};

		i2c@1100b000 {
			compatible = "mediatek,mt6580-i2c\0mediatek,i2c2";
			cell-index = <0x02>;
			reg = <0x1100b000 0x1000>;
			interrupts = <0x00 0x2a 0x08 0x00 0x34 0x08>;
			clock-div = <0x0a>;
			#address-cells = <0x01>;
			#size-cells = <0x00>;

			strobe_main@63 {
				compatible = "mediatek,strobe_main";
				reg = <0x63>;
				status = "okay";
			};

			msensor@0d {
				compatible = "mediatek,msensor";
				reg = <0x0d>;
				status = "okay";
			};

			gsensor@1f {
				compatible = "mediatek,gsensor";
				reg = <0x1f>;
				status = "okay";
			};

			gyro@68 {
				compatible = "mediatek,gyro";
				reg = <0x68>;
				status = "okay";
			};

			alsps@60 {
				compatible = "mediatek,alsps";
				reg = <0x60>;
				status = "okay";
			};
		};

		touch@0 {
			compatible = "mediatek,mt6580-touch";
			vtouch-supply = <0x0e>;
			interrupt-parent = <0x0a>;
			interrupts = <0x05 0x02>;
			debounce = <0x05 0x00>;
			status = "okay";
			tpd-resolution = <0x1e0 0x356>;
			use-tpd-button = <0x01>;
			tpd-key-num = <0x03>;
			tpd-key-local = <0x9e 0x8b 0xac 0x00>;
			tpd-key-dim-local = <0x5a 0x373 0x64 0x28 0xe6 0x373 0x64 0x28 0x172 0x373 0x64 0x28 0x00 0x00 0x00 0x00>;
			tpd-max-touch-num = <0x05>;
			tpd-filter-enable = <0x01>;
			tpd-filter-pixel-density = <0x7c>;
			tpd-filter-custom-prameters = <0x00 0x00 0x00 0x00 0x00 0x00 0x00 0x00 0x00 0x00 0x00 0x00>;
			tpd-filter-custom-speed = <0x00 0x00 0x00>;
			pinctrl-names = "default\0state_eint_as_int\0state_eint_output0\0state_eint_output1\0state_rst_output0\0state_rst_output1";
			pinctrl-0 = <0x0f>;
			pinctrl-1 = <0x10>;
			pinctrl-2 = <0x11>;
			pinctrl-3 = <0x12>;
			pinctrl-4 = <0x13>;
			pinctrl-5 = <0x14>;
		};

		accdet {
			compatible = "mediatek,mt6580-accdet";
			interrupt-parent = <0x0a>;
			interrupts = <0x00 0x08>;
			debounce = <0x00 0x3e800>;
			status = "okay";
			accdet-mic-vol = <0x07>;
			headset-mode-setting = <0x500 0x200 0x01 0x1f0 0x800 0x800 0x20>;
			accdet-plugout-debounce = <0x14>;
			accdet-mic-mode = <0x01>;
			headset-three-key-threshold = <0x00 0x5a 0xf0 0x1f4>;
			headset-four-key-threshold = <0x00 0x3b 0x7b 0xc3 0x1c2>;
			pinctrl-names = "default\0state_eint_as_int";
			pinctrl-0 = <0x15>;
			pinctrl-1 = <0x16>;
		};

		gse_1 {
			compatible = "mediatek, gse_1-eint";
			status = "okay";
			interrupt-parent = <0x0a>;
			interrupts = <0x01 0x08>;
			debounce = <0x01 0x00>;
		};

		spi@1100c000 {
			compatible = "mediatek,mt6580-spi";
			cell-index = <0x00>;
			reg = <0x1100c000 0x1000>;
			interrupts = <0x00 0x40 0x08>;
			mediatek,spi-padmacro = <0x00>;
		};

		THERM_CTRL@0x1100D000 {
			compatible = "mediatek,THERM_CTRL";
			reg = <0x1100d000 0x1000>;
			interrupts = <0x00 0x25 0x08>;
		};

		btif_tx@11000380 {
			compatible = "mediatek,btif_tx";
			reg = <0x11000380 0x80>;
			interrupts = <0x00 0x36 0x08>;
		};

		btif_rx@11000400 {
			compatible = "mediatek,btif_rx";
			reg = <0x11000400 0x80>;
			interrupts = <0x00 0x37 0x08>;
		};

		btif@1100e000 {
			compatible = "mediatek,btif";
			reg = <0x1100e000 0x1000>;
			interrupts = <0x00 0x43 0x08>;
		};

		mt3326-gps@0xffffffff {
			compatible = "mediatek,mt3326-gps";
		};

		BTCVSD@0x18000000 {
			compatible = "mediatek,audio_bt_cvsd";
			offset = <0xc00 0x02 0xfd0 0xfd4 0xfd8>;
			reg = <0x10001000 0x1000 0x18000000 0x10000 0x18080000 0x8000>;
			interrupts = <0x00 0x99 0x08>;
		};

		consys@18070000 {
			compatible = "mediatek,mt6580-consys";
			reg = <0x18070000 0x200 0x10007000 0x100 0x10000000 0x2000 0x10006000 0x1000 0x10005000 0x1000>;
			interrupts = <0x00 0x9a 0x08 0x00 0x9c 0x08>;
			vcn18-supply = <0x17>;
			vcn28-supply = <0x18>;
			vcn33_bt-supply = <0x19>;
			vcn33_wifi-supply = <0x1a>;
			pinctrl-names = "default\0gps_lna_state_init\0gps_lna_state_oh\0gps_lna_state_ol";
			pinctrl-0 = <0x1b>;
			pinctrl-1 = <0x1c>;
			pinctrl-2 = <0x1d>;
			pinctrl-3 = <0x1e>;
			status = "okay";
		};

		WIFI@0x180F0000 {
			compatible = "mediatek,WIFI";
			reg = <0x180f0000 0x5c>;
			interrupts = <0x00 0x9b 0x08>;
		};

		DISP_PWM@0x1100F000 {
			compatible = "mediatek,DISP_PWM";
			reg = <0x1100f000 0x1000>;
			interrupts = <0x00 0x21 0x08>;
		};

		USB0@0x11100000 {
			compatible = "mediatek,USB0";
			cell-index = <0x00>;
			reg = <0x11100000 0x10000 0x11110000 0x10000>;
			interrupts = <0x00 0x20 0x08>;
			mode = <0x02>;
			multipoint = <0x01>;
			dyn_fifo = <0x01>;
			soft_con = <0x01>;
			dma = <0x01>;
			num_eps = <0x10>;
			dma_channels = <0x08>;
			iddig_gpio = <0x07 0x03>;
			drvvbus_gpio = <0x08 0x03>;

			usbiddig {
				compatible = "mediatek,usb_iddig_eint";
			};
		};

		usbphy@0 {
			compatible = "usb-nop-xceiv";
		};

		audio@11140000 {
			compatible = "mediatek,audio";
			reg = <0x11140000 0x10000>;
			interrupts = <0x00 0x50 0x08>;
		};

		mt_soc_dl1_pcm@11140000 {
			compatible = "mediatek,mt_soc_pcm_dl1";
			reg = <0x11140000 0x1000>;
			interrupts = <0x00 0x50 0x08>;
			audclk-gpio = <0x1a 0x00>;
			audmiso-gpio = <0x1c 0x00>;
			audmosi-gpio = <0x1b 0x00>;
			pinctrl-names = "default\0audpmicclk-mode0\0audpmicclk-mode1";
			pinctrl-0 = <0x1f>;
			pinctrl-1 = <0x20>;
			pinctrl-2 = <0x21>;
			status = "okay";
		};

		mt_soc_ul1_PCM@11140000 {
			compatible = "mediatek,mt_soc_pcm_capture";
		};

		mt_soc_voice_md1@11140000 {
			compatible = "mediatek,mt_soc_pcm_voice_md1";
		};

		mt_soc_hdmi_pcm@11140000 {
			compatible = "mediatek,mt_soc_pcm_hdmi";
		};

		mt_soc_uldlloopback_pcm@11140000 {
			compatible = "mediatek,mt_soc_pcm_uldlloopback";
		};

		mt_soc_i2s0_pcm@11140000 {
			compatible = "mediatek,mt_soc_pcm_dl1_i2s0";
		};

		mt_soc_mrgrx_pcm@11140000 {
			compatible = "mediatek,mt_soc_pcm_mrgrx";
		};

		mt_soc_mrgrx_awb_pcm@11140000 {
			compatible = "mediatek,mt_soc_pcm_mrgrx_awb";
		};

		mt_soc_fm_i2s_pcm@0x11140000 {
			compatible = "mediatek,mt_soc_pcm_fm_i2s";
		};

		mt_soc_fm_i2s_awb_pcm@11140000 {
			compatible = "mediatek,mt_soc_pcm_fm_i2s_awb";
		};

		mt_soc_i2s0dl1_pcm@11140000 {
			compatible = "mediatek,mt_soc_pcm_dl1_i2s0Dl1";
		};

		mt_soc_dl1_awb_pcm@11140000 {
			compatible = "mediatek,mt_soc_pcm_dl1_awb";
		};

		mt_soc_voice_md1_bt@11140000 {
			compatible = "mediatek,mt_soc_pcm_voice_md1_bt";
		};

		mt_soc_voip_bt_out@11140000 {
			compatible = "mediatek,mt_soc_pcm_dl1_bt";
		};

		mt_soc_voip_bt_in@11140000 {
			compatible = "mediatek,mt_soc_pcm_bt_dai";
		};

		mt_soc_tdmrx_pcm@11140000 {
			compatible = "mediatek,mt_soc_tdm_capture";
		};

		mt_soc_fm_mrgtx_pcm@11140000 {
			compatible = "mediatek,mt_soc_pcm_fmtx";
		};

		mt_soc_ul2_pcm@11140000 {
			compatible = "mediatek,mt_soc_pcm_capture2";
		};

		mt_soc_i2s0_awb_pcm@11140000 {
			compatible = "mediatek,mt_soc_pcm_i2s0_awb";
		};

		mt_soc_voice_md2@11140000 {
			compatible = "mediatek,mt_soc_pcm_voice_md2";
		};

		mt_soc_routing_pcm@11140000 {
			compatible = "mediatek,mt_soc_pcm_routing";
		};

		mt_soc_voice_md2_bt@11140000 {
			compatible = "mediatek,mt_soc_pcm_voice_md2_bt";
		};

		mt_soc_hp_impedance_pcm@11140000 {
			compatible = "mediatek,Mt_soc_pcm_hp_impedance";
		};

		mt_soc_codec_name@11140000 {
			compatible = "mediatek,mt_soc_codec_63xx";
		};

		mt_soc_dummy_pcm@11140000 {
			compatible = "mediatek,mt_soc_pcm_dummy";
		};

		mt_soc_codec_dummy_name@11140000 {
			compatible = "mediatek,mt_soc_codec_dummy";
		};

		mt_soc_routing_dai_name@11140000 {
			compatible = "mediatek,mt_soc_dai_routing";
		};

		mt_soc_dai_name@11140000 {
			compatible = "mediatek,mt_soc_dai_stub";
		};

		mt_soc_dl2_pcm@11140000 {
			compatible = "mediatek,mt_soc_pcm_dl2";
		};

		AHB_MOM@0x11150000 {
			compatible = "mediatek,AHB_MOM";
			reg = <0x11150000 0x10000>;
		};

		MDI@0x11160000 {
			compatible = "mediatek,MDI";
			reg = <0x11160000 0x10000>;
		};

		G3D_CONFIG@0x13000000 {
			compatible = "mediatek,G3D_CONFIG";
			reg = <0x13000000 0x1000>;
		};

		MALI@0x13010000 {
			compatible = "mediatek,MALI";
			reg = <0x13010000 0x10000>;
		};

		mmsys_config@14000000 {
			compatible = "mediatek,mmsys_config";
			reg = <0x14000000 0x1000>;
			interrupts = <0x00 0x84 0x08>;
		};

		mdp_rdma@14001000 {
			compatible = "mediatek,mdp_rdma";
			reg = <0x14001000 0x1000>;
			interrupts = <0x00 0x71 0x08>;
		};

		mdp_rsz0@14002000 {
			compatible = "mediatek,mdp_rsz0";
			reg = <0x14002000 0x1000>;
			interrupts = <0x00 0x72 0x08>;
		};

		mdp_rsz1@14003000 {
			compatible = "mediatek,mdp_rsz1";
			reg = <0x14003000 0x1000>;
			interrupts = <0x00 0x73 0x08>;
		};

		mdp_wdma@14004000 {
			compatible = "mediatek,mdp_wdma";
			reg = <0x14004000 0x1000>;
			interrupts = <0x00 0x75 0x08>;
		};

		mdp_wrot@14005000 {
			compatible = "mediatek,mdp_wrot";
			reg = <0x14005000 0x1000>;
			interrupts = <0x00 0x76 0x08>;
		};

		mdp_tdshp@14006000 {
			compatible = "mediatek,mdp_tdshp";
			reg = <0x14006000 0x1000>;
			interrupts = <0x00 0x74 0x08>;
		};

		lcm {
			compatible = "mediatek,mt6580-lcm";
		};

		DISPSYS@0x14007000 {
			compatible = "mediatek,DISPSYS";
			reg = <0x14000000 0x1000 0x14007000 0x1000 0x14008000 0x1000 0x14009000 0x1000 0x1400a000 0x1000 0x1400b000 0x1000 0x1400c000 0x1000 0x1400d000 0x1000 0x1400e000 0x1000 0x1400f000 0x1000 0x14010000 0x1000 0x14011000 0x1000 0x14012000 0x1000 0x14013000 0x1000 0x1100f000 0x1000 0x14015000 0x1000 0x14016000 0x1000 0x14017000 0x1000 0x14018000 0x1000>;
			interrupts = <0x00 0x00 0x08 0x00 0x77 0x08 0x00 0x00 0x08 0x00 0x79 0x08 0x00 0x00 0x08 0x00 0x7b 0x08 0x00 0x7c 0x08 0x00 0x00 0x08 0x00 0x7e 0x08 0x00 0x7f 0x08 0x00 0x80 0x08 0x00 0x00 0x08 0x00 0x82 0x08 0x00 0x00 0x08 0x00 0x00 0x08 0x00 0x70 0x08 0x00 0x00 0x08 0x00 0x00 0x08 0x00 0x00 0x08>;
		};

		DISP_OVL0@0x14007000 {
			compatible = "mediatek,DISP_OVL0";
			reg = <0x14007000 0x1000>;
			interrupts = <0x00 0x77 0x08>;
		};

		DISP_OVL1@0x14008000 {
			compatible = "mediatek,DISP_OVL1";
			reg = <0x14008000 0x1000>;
		};

		DISP_RDMA0@0x14009000 {
			compatible = "mediatek,DISP_RDMA0";
			reg = <0x14009000 0x1000>;
			interrupts = <0x00 0x79 0x08>;
		};

		DISP_RDMA1@0x1400A000 {
			compatible = "mediatek,DISP_RDMA1";
			reg = <0x1400a000 0x1000>;
		};

		DISP_WDMA@0x1400B000 {
			compatible = "mediatek,DISP_WDMA";
			reg = <0x1400b000 0x1000>;
			interrupts = <0x00 0x7b 0x08>;
		};

		DISP_COLOR@0x1400C000 {
			compatible = "mediatek,DISP_COLOR";
			reg = <0x1400c000 0x1000>;
			interrupts = <0x00 0x7c 0x08>;
		};

		DISP_CCORR@0x1400D000 {
			compatible = "mediatek,DISP_CCORR";
			reg = <0x1400d000 0x1000>;
		};

		DISP_AAL@0x1400E000 {
			compatible = "mediatek,DISP_AAL";
			reg = <0x1400e000 0x1000>;
			interrupts = <0x00 0x7e 0x08>;
		};

		DISP_GAMMA@0x1400F000 {
			compatible = "mediatek,DISP_GAMMA";
			reg = <0x1400f000 0x1000>;
			interrupts = <0x00 0x7f 0x08>;
		};

		DISP_DITHER@0x14010000 {
			compatible = "mediatek,DISP_DITHER";
			reg = <0x14010000 0x1000>;
			interrupts = <0x00 0x80 0x08>;
		};

		DISP_UFOE@0x14011000 {
			compatible = "mediatek,DISP_UFOE";
			reg = <0x14011000 0x1000>;
		};

		DSI@0x14012000 {
			compatible = "mediatek,DSI";
			reg = <0x14012000 0x1000>;
		};

		DPI@0x14013000 {
			compatible = "mediatek,DPI";
			reg = <0x14013000 0x1000>;
		};

		PTP_FSM@0x1100D000 {
			compatible = "mediatek,PTP_FSM";
			reg = <0x1100d000 0x1000>;
			interrupts = <0x00 0x2b 0x08>;
		};

		MM_MUTEX@0x14015000 {
			compatible = "mediatek,MM_MUTEX";
			reg = <0x14015000 0x1000>;
			interrupts = <0x00 0x70 0x08>;
		};

		SMI_LARB0@0x14016000 {
			compatible = "mediatek,SMI_LARB0";
			reg = <0x14016000 0x1000>;
			interrupts = <0x00 0x85 0x08>;
		};

		SMI_COMMON@0x14017000 {
			compatible = "mediatek,SMI_COMMON";
			reg = <0x14017000 0x1000 0x14016000 0x1000 0x15001000 0x1000>;
		};

		MIPI_TX_CONFIG@0x14018000 {
			compatible = "mediatek,MIPI_TX_CONFIG";
			reg = <0x14018000 0x1000>;
		};

		ISPSYS@0x15000000 {
			compatible = "mediatek,ISPSYS";
			reg = <0x15004000 0x9000 0x15000000 0x10000 0x10011000 0x4000 0x10017000 0x1000>;
			interrupts = <0x00 0x8e 0x08 0x00 0x8b 0x08>;
		};

		ISP_SYSR@0x15000000 {
			compatible = "mediatek,ISP_SYSR";
		};

		ISP_PIPEM@0x15000000 {
			compatible = "mediatek,ISP_PIPEM";
		};

		kd_camera_hw1@15008000 {
			compatible = "mediatek,camera_hw";
			reg = <0x15008000 0x1000>;
			vcama-supply = <0x22>;
			vcamd-supply = <0x23>;
			vcamaf-supply = <0x24>;
			vcamio-supply = <0x25>;
			vcamd_main2-supply = <0x23>;
			vcamd_sub-supply = <0x23>;
			vcamio_main2-supply = <0x25>;
			vcamio_sub-supply = <0x25>;
			vcama_main2-supply = <0x22>;
			vcama_sub-supply = <0x22>;
			status = "okay";
			pinctrl-names = "default\0cam0_rst0\0cam0_rst1\0cam0_pnd0\0cam0_pnd1\0cam1_rst0\0cam1_rst1\0cam1_pnd0\0cam1_pnd1\0cam_ldo0_0\0cam_ldo0_1\0cam1_gpio_serial\0cam1_gpio_mipi\0cam_mclk1_enable\0cam_mclk1_disable\0cam_mclk2_enable\0cam_mclk2_disable";
			pinctrl-0 = <0x26>;
			pinctrl-1 = <0x27>;
			pinctrl-2 = <0x28>;
			pinctrl-3 = <0x29>;
			pinctrl-4 = <0x2a>;
			pinctrl-5 = <0x2b>;
			pinctrl-6 = <0x2c>;
			pinctrl-7 = <0x2d>;
			pinctrl-8 = <0x2e>;
			pinctrl-9 = <0x2f>;
			pinctrl-10 = <0x30>;
			pinctrl-11 = <0x31>;
			pinctrl-12 = <0x32>;
			pinctrl-13 = <0x33>;
			pinctrl-14 = <0x34>;
			pinctrl-15 = <0x35>;
			pinctrl-16 = <0x36>;
		};

		kd_camera_hw2@15008000 {
			compatible = "mediatek,camera_hw2";
			reg = <0x15008000 0x1000>;
		};

		seninf_top@15008000 {
			compatible = "mediatek,SENINF_TOP";
			reg = <0x15008000 0x1000>;
			interrupts = <0x00 0x8e 0x08>;
		};

		CAM_0@0x15004000 {
			compatible = "mediatek,CAM_0";
			reg = <0x15004000 0x1000>;
			interrupts = <0x00 0x8b 0x08>;
		};

		CAM_1@0x15005000 {
			compatible = "mediatek,CAM_1";
			reg = <0x15005000 0x1000>;
		};

		VENC@0x15009000 {
			compatible = "mediatek,VENC";
			reg = <0x15009000 0x1000>;
			interrupts = <0x00 0x8a 0x08>;
		};

		VDEC@0x1500B000 {
			compatible = "mediatek,VDEC";
			reg = <0x1500b000 0x1000>;
			interrupts = <0x00 0x89 0x08>;
		};

		SMI_LARB1@0x15001000 {
			compatible = "mediatek,SMI_LARB1";
			reg = <0x15001000 0x1000>;
			interrupts = <0x00 0x88 0x08>;
		};

		IMGSYS_CONFIG@0x15000000 {
			compatible = "mediatek,IMGSYS_CONFIG";
			reg = <0x15000000 0x1000>;
		};

		hwmsensor@0 {
			compatible = "mediatek,hwmsensor";
		};

		gsensor@0 {
			compatible = "mediatek,gsensor";
		};

		als_ps@0 {
			compatible = "mediatek,als_ps";
			pinctrl-names = "pin_default\0pin_cfg";
			pinctrl-0 = <0x37>;
			pinctrl-1 = <0x38>;
			status = "okay";
		};

		m_acc_pl@0 {
			compatible = "mediatek,m_acc_pl";
		};

		m_alsps_pl@0 {
			compatible = "mediatek,m_alsps_pl";
		};

		sensorHub@0 {
			compatible = "mediatek,sensorHub";
		};

		shf@0 {
			compatible = "mediatek,shf";
		};

		m_batch_pl@0 {
			compatible = "mediatek,m_batch_pl";
		};

		gyroscope@0 {
			compatible = "mediatek,gyroscope";
			pinctrl-names = "pin_default\0pin_cfg";
			pinctrl-0 = <0x39>;
			pinctrl-1 = <0x3a>;
			status = "okay";
		};

		m_gyro_pl@0 {
			compatible = "mediatek,m_gyro_pl";
		};

		barometer@0 {
			compatible = "mediatek,barometer";
		};

		m_baro_pl@0 {
			compatible = "mediatek,m_baro_pl";
		};

		msensor@0 {
			compatible = "mediatek,msensor";
		};

		m_mag_pl@0 {
			compatible = "mediatek,m_mag_pl";
		};

		orientation@0 {
			compatible = "mediatek,orientation";
		};

		pedometer@0 {
			compatible = "mediatek,pedometer";
		};

		m_pdr_pl@0 {
			compatible = "mediatek,m_pdr_pl";
		};

		step_counter@0 {
			compatible = "mediatek,step_counter";
		};

		m_step_c_pl@0 {
			compatible = "mediatek,m_step_c_pl";
		};

		in_pocket@0 {
			compatible = "mediatek,in_pocket";
		};

		m_inpk_pl@0 {
			compatible = "mediatek,m_inpk_pl";
		};

		shake@0 {
			compatible = "mediatek,shake";
		};

		m_shk_pl@0 {
			compatible = "mediatek,m_shk_pl";
		};

		face_down@0 {
			compatible = "mediatek,face_down";
		};

		m_fdn_pl@0 {
			compatible = "mediatek,m_fdn_pl";
		};

		activity@0 {
			compatible = "mediatek,activity";
		};

		m_act_pl@0 {
			compatible = "mediatek,m_act_pl";
		};

		heart_rate@0 {
			compatible = "mediatek,heart_rate";
		};

		m_hrm_pl@0 {
			compatible = "mediatek,m_hrm_pl";
		};

		tilt_detector@0 {
			compatible = "mediatek,tilt_detector";
		};

		m_tilt_pl@0 {
			compatible = "mediatek,m_tilt_pl";
		};

		wake_gesture@0 {
			compatible = "mediatek,wake_gesture";
		};

		m_wag_pl@0 {
			compatible = "mediatek,m_wag_pl";
		};

		glance_gesture@0 {
			compatible = "mediatek,glance_gesture";
		};

		m_glg_pl@0 {
			compatible = "mediatek,m_glg_pl";
		};

		pick_up@0 {
			compatible = "mediatek,pick_up";
		};

		m_pkup_pl@0 {
			compatible = "mediatek,m_pkup_pl";
		};

		als {
			compatible = "mediatek, als-eint";
			interrupt-parent = <0x0a>;
			interrupts = <0x06 0x08>;
			debounce = <0x06 0x00>;
			status = "okay";
		};

		mtkfb@0 {
			compatible = "mediatek,mtkfb";
		};

		dsi_te {
			compatible = "mediatek, dsi_te-eint";
			interrupt-parent = <0x0a>;
			interrupts = <0x44 0x01>;
			debounce = <0x44 0x00>;
			status = "okay";
		};
	};

	MOBICORE {
		compatible = "trustonic,mobicore";
		interrupts = <0x00 0x97 0x01>;
	};

	mt_pmic_regulator {
		compatible = "mediatek,mt_pmic";

		buck_regulators {
			compatible = "mediatek,mt_pmic_buck_regulators";

			buck_vpa {
				regulator-name = "vpa";
				regulator-min-microvolt = <0x7a120>;
				regulator-max-microvolt = <0x37b1d0>;
				regulator-ramp-delay = <0xc350>;
				regulator-enable-ramp-delay = <0xb4>;
			};

			buck_vproc {
				regulator-name = "vproc";
				regulator-min-microvolt = <0xaae60>;
				regulator-max-microvolt = <0x16caf6>;
				regulator-ramp-delay = <0x186a>;
				regulator-enable-ramp-delay = <0xb4>;
				regulator-always-on;
				regulator-boot-on;
			};
		};

		ldo_regulators {
			compatible = "mediatek,mt_pmic_ldo_regulators";

			ldo_vcn28 {
				regulator-name = "vcn28";
				regulator-min-microvolt = <0x1b7740>;
				regulator-max-microvolt = <0x2ab980>;
				regulator-enable-ramp-delay = <0x108>;
				regulator-default-on = <0x00>;
				status = "okay";
				linux,phandle = <0x18>;
				phandle = <0x18>;
			};

			ldo_vtcxo {
				regulator-name = "vtcxo";
				regulator-min-microvolt = <0x2191c0>;
				regulator-max-microvolt = <0x2191c0>;
				regulator-enable-ramp-delay = <0x6e>;
				linux,phandle = <0x3b>;
				phandle = <0x3b>;
			};

			ldo_va {
				regulator-name = "va";
				regulator-min-microvolt = <0x1b7740>;
				regulator-max-microvolt = <0x2625a0>;
				regulator-enable-ramp-delay = <0x6e>;
				linux,phandle = <0x3c>;
				phandle = <0x3c>;
			};

			ldo_vcama {
				regulator-name = "vcama";
				regulator-min-microvolt = <0x16e360>;
				regulator-max-microvolt = <0x2ab980>;
				regulator-enable-ramp-delay = <0x108>;
				regulator-default-on = <0x00>;
				status = "okay";
				linux,phandle = <0x22>;
				phandle = <0x22>;
			};

			ldo_vcn33_bt {
				regulator-name = "vcn33_bt";
				regulator-min-microvolt = <0x325aa0>;
				regulator-max-microvolt = <0x36ee80>;
				regulator-enable-ramp-delay = <0x108>;
				linux,phandle = <0x19>;
				phandle = <0x19>;
			};

			ldo_vcn33_wifi {
				regulator-name = "vcn33_wifi";
				regulator-min-microvolt = <0x325aa0>;
				regulator-max-microvolt = <0x36ee80>;
				regulator-enable-ramp-delay = <0x108>;
				linux,phandle = <0x1a>;
				phandle = <0x1a>;
			};

			ldo_vio28 {
				regulator-name = "vio28";
				regulator-min-microvolt = <0x2ab980>;
				regulator-max-microvolt = <0x2ab980>;
				regulator-enable-ramp-delay = <0x108>;
				regulator-boot-on;
				linux,phandle = <0x3d>;
				phandle = <0x3d>;
			};

			ldo_vsim1 {
				regulator-name = "vsim1";
				regulator-min-microvolt = <0x1b7740>;
				regulator-max-microvolt = <0x2dc6c0>;
				regulator-enable-ramp-delay = <0x108>;
				regulator-default-on = <0x00>;
				status = "okay";
				linux,phandle = <0x3e>;
				phandle = <0x3e>;
			};

			ldo_vsim2 {
				regulator-name = "vsim2";
				regulator-min-microvolt = <0x1b7740>;
				regulator-max-microvolt = <0x2dc6c0>;
				regulator-enable-ramp-delay = <0x108>;
				regulator-default-on = <0x00>;
				status = "okay";
				linux,phandle = <0x3f>;
				phandle = <0x3f>;
			};

			ldo_vusb {
				regulator-name = "vusb";
				regulator-min-microvolt = <0x325aa0>;
				regulator-max-microvolt = <0x325aa0>;
				regulator-enable-ramp-delay = <0x108>;
				regulator-boot-on;
				linux,phandle = <0x40>;
				phandle = <0x40>;
			};

			ldo_vgp1 {
				regulator-name = "vgp1";
				regulator-min-microvolt = <0x124f80>;
				regulator-max-microvolt = <0x325aa0>;
				regulator-enable-ramp-delay = <0x108>;
				regulator-default-on = <0x00>;
				status = "okay";
				linux,phandle = <0x0e>;
				phandle = <0x0e>;
			};

			ldo_vgp2 {
				regulator-name = "vgp2";
				regulator-min-microvolt = <0x124f80>;
				regulator-max-microvolt = <0x2dc6c0>;
				regulator-enable-ramp-delay = <0x108>;
				regulator-default-on = <0x00>;
				status = "okay";
				linux,phandle = <0x41>;
				phandle = <0x41>;
			};

			ldo_vemc_3v3 {
				regulator-name = "vemc3v3";
				regulator-min-microvolt = <0x2dc6c0>;
				regulator-max-microvolt = <0x325aa0>;
				regulator-enable-ramp-delay = <0x108>;
				regulator-boot-on;
				regulator-default-on = <0x00>;
				status = "okay";
				linux,phandle = <0x42>;
				phandle = <0x42>;
			};

			ldo_vcamaf {
				regulator-name = "vcamaf";
				regulator-min-microvolt = <0x124f80>;
				regulator-max-microvolt = <0x325aa0>;
				regulator-enable-ramp-delay = <0x108>;
				regulator-default-on = <0x00>;
				status = "okay";
				linux,phandle = <0x24>;
				phandle = <0x24>;
			};

			ldo_vmc {
				regulator-name = "vmc";
				regulator-min-microvolt = <0x1b7740>;
				regulator-max-microvolt = <0x325aa0>;
				regulator-enable-ramp-delay = <0x2c>;
				regulator-boot-on;
				regulator-default-on = <0x00>;
				status = "okay";
				linux,phandle = <0x43>;
				phandle = <0x43>;
			};

			ldo_vmch {
				regulator-name = "vmch";
				regulator-min-microvolt = <0x2dc6c0>;
				regulator-max-microvolt = <0x325aa0>;
				regulator-enable-ramp-delay = <0x2c>;
				regulator-boot-on;
				regulator-default-on = <0x00>;
				status = "okay";
				linux,phandle = <0x44>;
				phandle = <0x44>;
			};

			ldo_vibr {
				regulator-name = "vibr";
				regulator-min-microvolt = <0x124f80>;
				regulator-max-microvolt = <0x325aa0>;
				regulator-enable-ramp-delay = <0x2c>;
				regulator-default-on = <0x00>;
				status = "okay";
				linux,phandle = <0x45>;
				phandle = <0x45>;
			};

			ldo_vrtc {
				regulator-name = "vrtc";
				regulator-min-microvolt = <0x2ab980>;
				regulator-max-microvolt = <0x2ab980>;
				regulator-enable-ramp-delay = <0x2c>;
				linux,phandle = <0x46>;
				phandle = <0x46>;
			};

			ldo_vm {
				regulator-name = "vm";
				regulator-min-microvolt = <0x124f80>;
				regulator-max-microvolt = <0x1b7740>;
				regulator-enable-ramp-delay = <0x108>;
				regulator-boot-on;
				regulator-default-on = <0x00>;
				status = "okay";
				linux,phandle = <0x47>;
				phandle = <0x47>;
			};

			ldo_vrf18 {
				regulator-name = "vrf18";
				regulator-min-microvolt = <0x1b7740>;
				regulator-max-microvolt = <0x1b7740>;
				regulator-enable-ramp-delay = <0xdc>;
				regulator-default-on = <0x00>;
				status = "okay";
				linux,phandle = <0x48>;
				phandle = <0x48>;
			};

			ldo_vio18 {
				regulator-name = "vio18";
				regulator-min-microvolt = <0x1b7740>;
				regulator-max-microvolt = <0x1b7740>;
				regulator-enable-ramp-delay = <0x108>;
				regulator-boot-on;
				linux,phandle = <0x49>;
				phandle = <0x49>;
			};

			ldo_vcamd {
				regulator-name = "vcamd";
				regulator-min-microvolt = <0x124f80>;
				regulator-max-microvolt = <0x1b7740>;
				regulator-enable-ramp-delay = <0x108>;
				regulator-default-on = <0x00>;
				status = "okay";
				linux,phandle = <0x23>;
				phandle = <0x23>;
			};

			ldo_vcamio {
				regulator-name = "vcamio";
				regulator-min-microvolt = <0x1b7740>;
				regulator-max-microvolt = <0x1b7740>;
				regulator-enable-ramp-delay = <0xdc>;
				linux,phandle = <0x4a>;
				phandle = <0x4a>;
			};

			ldo_vgp3 {
				regulator-name = "vgp3";
				regulator-min-microvolt = <0x124f80>;
				regulator-max-microvolt = <0x1b7740>;
				regulator-enable-ramp-delay = <0x108>;
				regulator-default-on = <0x00>;
				status = "okay";
				linux,phandle = <0x4b>;
				phandle = <0x4b>;
			};

			ldo_vcn_1v8 {
				regulator-name = "vcn1v8";
				regulator-min-microvolt = <0x1b7740>;
				regulator-max-microvolt = <0x1b7740>;
				regulator-enable-ramp-delay = <0x2c>;
				regulator-default-on = <0x00>;
				status = "okay";
				linux,phandle = <0x17>;
				phandle = <0x17>;
			};

			vcanio_ldo_reg {
				regulator-name = "vcanio";
				regulator-default-on = <0x00>;
				status = "okay";
				linux,phandle = <0x25>;
				phandle = <0x25>;
			};

			vcn33_ldo_reg {
				regulator-name = "vcn33";
				regulator-default-on = <0x00>;
				status = "okay";
			};
		};

		regulators_supply {
			compatible = "mediatek,mt_pmic_regulator_supply";
			vcn28-supply = <0x18>;
			vtcxo-supply = <0x3b>;
			va-supply = <0x3c>;
			vcn33_bt-supply = <0x19>;
			vcn33_wifi-supply = <0x1a>;
			vio28-supply = <0x3d>;
			vsim1-supply = <0x3e>;
			vsim2-supply = <0x3f>;
			vusb-supply = <0x40>;
			vgp1-supply = <0x0e>;
			vgp2-supply = <0x41>;
			vemc_3v3-supply = <0x42>;
			vcamaf-supply = <0x24>;
			vmc-supply = <0x43>;
			vmch-supply = <0x44>;
			vibr-supply = <0x45>;
			vrtc-supply = <0x46>;
			vm-supply = <0x47>;
			vrf18-supply = <0x48>;
			vio18-supply = <0x49>;
			vcamd-supply = <0x23>;
			vcamio-supply = <0x4a>;
			vgp3-supply = <0x4b>;
			vcn_1v8-supply = <0x17>;
		};
	};

	rf_clock_buffer {
		compatible = "mediatek,rf_clock_buffer";
		#mediatek,clkbuf-quantity = <0x04>;
		#mediatek,clkbuf-config = <0x02 0x01 0x01 0x01>;
		mediatek,clkbuf-quantity = <0x04>;
		mediatek,clkbuf-config = <0x02 0x02 0x01 0x01>;
		status = "okay";
	};

	aeon_gpio {
		compatible = "mediatek,aeon_gpio";
		pinctrl-names = "default\0aeon_chr_ce0\0aeon_chr_ce1\0aeon_factory_id\0aeon_flash_enf0\0aeon_flash_enf1\0aeon_flash_enm0\0aeon_flash_enm1\0aeon_flash_enm_pwm";
		pinctrl-0 = <0x4c>;
		pinctrl-1 = <0x4d>;
		pinctrl-2 = <0x4e>;
		pinctrl-3 = <0x4f>;
		pinctrl-4 = <0x50>;
		pinctrl-5 = <0x51>;
		pinctrl-6 = <0x52>;
		pinctrl-7 = <0x53>;
		pinctrl-8 = <0x54>;
		status = "okay";
	};

	hall {
		compatible = "mediatek, hall-eint";
		pinctrl-names = "pin_default\0pin_cfg";
		pinctrl-0 = <0x55>;
		pinctrl-1 = <0x56>;
		status = "okay";
	};

	trusty {
		compatible = "android,trusty-smc-v1";
		ranges;
		#address-cells = <0x02>;
		#size-cells = <0x02>;

		irq {
			compatible = "android,trusty-irq-v1";
		};

		log {
			compatible = "android,trusty-log-v1";
		};

		virtio {
			compatible = "android,trusty-virtio-v1";
		};
	};

	led@0 {
		compatible = "mediatek,red";
		led_mode = <0x03>;
		data = <0x01>;
		pwm_config = <0x00 0x00 0x00 0x00 0x00>;
	};

	led@1 {
		compatible = "mediatek,green";
		led_mode = <0x03>;
		data = <0x02>;
		pwm_config = <0x00 0x00 0x00 0x00 0x00>;
	};

	led@2 {
		compatible = "mediatek,blue";
		led_mode = <0x00>;
		data = <0x01>;
		pwm_config = <0x00 0x00 0x00 0x00 0x00>;
	};

	led@3 {
		compatible = "mediatek,jogball-backlight";
		led_mode = <0x00>;
		data = <0x01>;
		pwm_config = <0x00 0x00 0x00 0x00 0x00>;
	};

	led@4 {
		compatible = "mediatek,keyboard-backlight";
		led_mode = <0x00>;
		data = <0x01>;
		pwm_config = <0x00 0x00 0x00 0x00 0x00>;
	};

	led@5 {
		compatible = "mediatek,button-backlight";
		led_mode = <0x00>;
		data = <0x01>;
		pwm_config = <0x00 0x00 0x00 0x00 0x00>;
	};

	led@6 {
		compatible = "mediatek,lcd-backlight";
		led_mode = <0x05>;
		data = <0x01>;
		pwm_config = <0x00 0x00 0x00 0x00 0x00>;
	};

	vibrator@0 {
		compatible = "mediatek,vibrator";
		vib_timer = <0x19>;
		vib_limit = <0x09>;
		vib_vol = <0x06>;
	};

	cust_accel@0 {
		compatible = "mediatek,kx023";
		i2c_num = <0x02>;
		i2c_addr = <0x1f 0x00 0x00 0x00>;
		direction = <0x05>;
		power_id = <0xffff>;
		power_vol = <0x00>;
		firlen = <0x00>;
		is_batch_supported = <0x00>;
	};

	cust_accel@1 {
		compatible = "mediatek,mc3xxx";
		i2c_num = <0x02>;
		i2c_addr = <0x4c 0x00 0x00 0x00>;
		direction = <0x07>;
		power_id = <0xffff>;
		power_vol = <0x00>;
		firlen = <0x00>;
		is_batch_supported = <0x00>;
	};

	cust_alsps@0 {
		compatible = "mediatek,stk3x1x";
		i2c_num = <0x02>;
		i2c_addr = <0x48 0x00 0x00 0x00>;
		polling_mode_ps = <0x00>;
		polling_mode_als = <0x01>;
		power_id = <0xffff>;
		power_vol = <0x00>;
		als_level = <0x0a 0x14 0x24 0x3b 0x50 0x78 0xb4 0x104 0x1c2 0x34d 0x470 0x609 0x93c 0x122f 0x1b46>;
		als_value = <0x00 0x0a 0x28 0x41 0x5a 0x91 0xe1 0x12c 0x226 0x3a2 0x4e2 0x6a4 0xa28 0x1400 0x1e00 0x2800>;
		state_val = <0x00>;
		psctrl_val = <0x71>;
		alsctrl_val = <0x39>;
		ledctrl_val = <0xff>;
		wait_val = <0x07>;
		ps_high_thd_val = <0x6a4>;
		ps_low_thd_val = <0x5dc>;
		ps_threshold_high = <0x1a>;
		ps_threshold_low = <0x15>;
		is_batch_supported_ps = <0x00>;
		is_batch_supported_als = <0x00>;
	};

	cust_mag@0 {
		compatible = "mediatek,af7133E";
		i2c_num = <0x02>;
		i2c_addr = <0x1e 0x00 0x00 0x00>;
		direction = <0x00>;
		power_id = <0xffff>;
		power_vol = <0x00>;
		is_batch_supported = <0x00>;
	};

	cust_gyro@0 {
		compatible = "mediatek,itg1010";
		i2c_num = <0x02>;
		i2c_addr = <0x68 0x00 0x00 0x00>;
		direction = <0x03>;
		power_id = <0xffff>;
		power_vol = <0x00>;
		firlen = <0x00>;
		is_batch_supported = <0x00>;
	};
};
